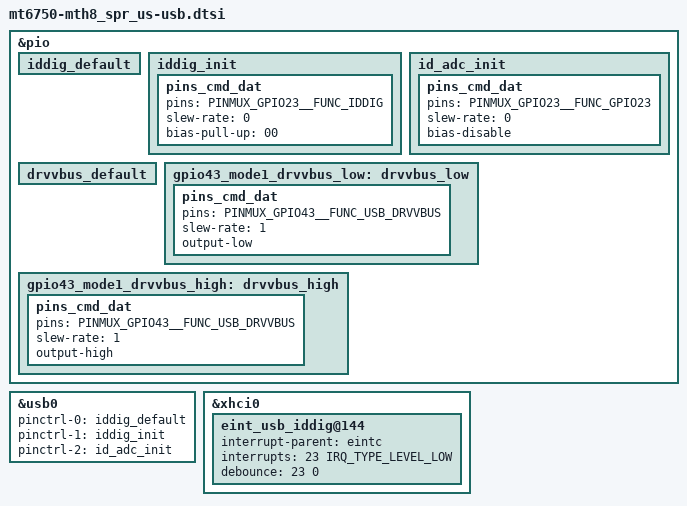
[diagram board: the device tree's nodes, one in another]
/*
 * LG Electronics TH8 usb device tree source
 *
 * Copyright (c) 2017 LG Electronics Co., Ltd.
 *              http://www.lge.com
 *
 */

&pio {
	iddig_default: iddig_default {
	};

	iddig_init: iddig_init {
		pins_cmd_dat {
			pins = <PINMUX_GPIO23__FUNC_IDDIG>;
			slew-rate = <0>;
			bias-pull-up = <00>;
		};
	};

	id_adc_init: id_adc_init {
		pins_cmd_dat {
			pins = <PINMUX_GPIO23__FUNC_GPIO23>;
			slew-rate = <0>;
			bias-disable;
		};
	};
};

&pio {
	drvvbus_default: drvvbus_default {
	};

	gpio43_mode1_drvvbus_low: drvvbus_low {
		pins_cmd_dat {
			pins = <PINMUX_GPIO43__FUNC_USB_DRVVBUS>;
			slew-rate = <1>;
			output-low;
		};
	};

	gpio43_mode1_drvvbus_high: drvvbus_high {
		pins_cmd_dat {
			pins = <PINMUX_GPIO43__FUNC_USB_DRVVBUS>;
			slew-rate = <1>;
			output-high;
		};
	};
};

&usb0 {
	pinctrl-names = "iddig_default", "iddig_init", "id_adc_init";
	pinctrl-0 = <&iddig_default>;
	pinctrl-1 = <&iddig_init>;
	pinctrl-2 = <&id_adc_init>;
	status = "okay";
};

&xhci0 {
	eint_usb_iddig@144 {
		interrupt-parent = <&eintc>;
		interrupts = <23 IRQ_TYPE_LEVEL_LOW>;
		debounce = <23 0>;
	};
};
